# MCXN947_cm33_core0 register map
Vendor: nxp.com; File version: 1.0
CPU: CM33 r2p0, little endian, MPU, FPU, VTOR, 3 interrupt priority bits
Registers are 32-bit, read-write, reset 0x0 unless marked. A register's access mark holds for its fields unless they carry their own. Offsets are from the block's base; [hi:lo] are bit positions; {n}, {i} and the like mark numbered series; 'fields as' and 'values as' point back to an identical list.

## TDET0 — TDET
Base 0x40058000
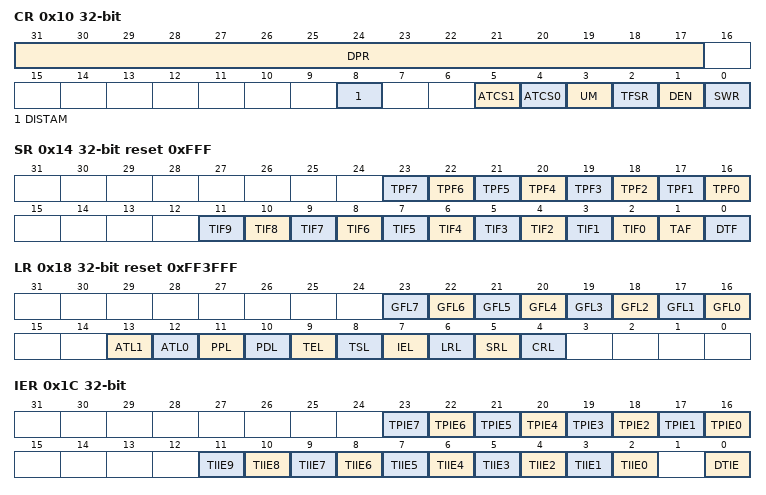
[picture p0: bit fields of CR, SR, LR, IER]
0x10 CR — Control
  [31:17] DPR — Digital Tamper Prescaler
  [8] DISTAM — Disable Prescaler On Tamper
    0=NO_EFFECT; 1=AUTO_DIS (Automatically disables the prescaler after tamper detection)
  [5] ATCS1 — Active Tamper Clock Source
    0=FREQ_1_HZ (1 Hz prescaler clock); 1=FREQ_64_HZ (64 Hz prescaler clock)
  [4] ATCS0 — Active Tamper Clock Source
    values as ATCS1
  [3] UM — Update Mode
    0=NO_EFFECT; 1=CLEAR_INTS (Allows the clearing of interrupts)
  [2] TFSR — Tamper Force System Reset
    0=NO_RESET (Do not force chip reset); 1=RESET (Force chip reset)
  [1] DEN — Digital Tamper Enable
    0=DISABLE (Disables TDET clock and prescaler); 1=ENABLE (Enables TDET clock and prescaler)
  [0] SWR — Software Reset
    0=NO_EFFECT; 1=SW_RESET (Perform a software reset)
0x14 SR reset 0xFFF write-1-clears — Status
  [n+16] TPF{n} write-1-clears (n=0..7) — Tamper Pin n Flag
    0=NO_DET (Pin tamper not detected); 1=DET (Pin tamper detected)
  [n+2] TIF{n} write-1-clears (n=0..9) — Tamper Input n Flag
    0=NO_DET (On-chip tamper not detected); 1=DET (On-chip tamper detected)
  [1] TAF write-1-clears — Tamper Acknowledge Flag
    0=NOT_OCCUR (Digital Tamper Flag (SR[DTF]) is clear or chip reset has not occurred after Digital Tamper Flag (SR[DTF]) was set.); 1=OCCUR (Chip reset has occurred after Digital Tamper Flag (SR[DTF]) was set.)
  [0] DTF write-1-clears — Digital Tamper Flag
    0=NO_DET (TDET tampering not detected); 1=DET (TDET tampering detected)
0x18 LR reset 0xFF3FFF — Lock
  [all] fields
    0=LOCK (Locked and writes are ignored); 1=NOT_LOCK (Not locked and writes complete as normal)
  [n+16] GFL{n} (n=0..7) — Glitch Filter Lock
  [13] ATL1 — Active Tamper Lock
  [12] ATL0 — Active Tamper Lock
  [11] PPL — Pin Polarity Lock
  [10] PDL — Pin Direction Lock
  [9] TEL — Tamper Enable Lock
  [8] TSL — Tamper Seconds Lock
  [7] IEL — Interrupt Enable Lock
  [6] LRL — Lock Register Lock
  [5] SRL — Status Register Lock
  [4] CRL — Control Register Lock
0x1C IER — Interrupt Enable
  [all] fields
    0=DISABLE (Disables); 1=ENABLE (Enables)
  [n+16] TPIE{n} (n=0..7) — Tamper Pin n Interrupt Enable
  [n+2] TIIE{n} (n=0..9) — Tamper Input n Interrupt Enable
  [0] DTIE — Digital Tamper Interrupt Enable
0x20 TSR — Tamper Seconds
  [31:0] TTS — Tamper Time Seconds
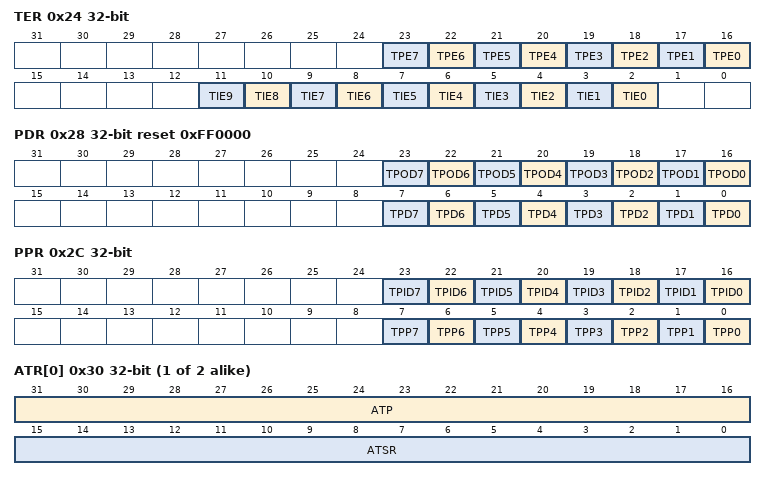
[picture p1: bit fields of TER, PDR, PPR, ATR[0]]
0x24 TER — Tamper Enable
  [all] fields
    0=DISABLE (Disables); 1=ENABLE (Enables)
  [n+16] TPE{n} (n=0..7) — Tamper Pin Enable
  [n+2] TIE{n} (n=0..9) — Tamper Input Enable
0x28 PDR reset 0xFF0000 — Pin Direction
  [n+16] TPOD{n} ro (n=0..7) — Tamper Pin Output Data
    0=ZERO; 1=ONE
  [n] TPD{n} (n=0..7) — Tamper Pin Direction
    0=INPUT; 1=OUTPUT (Output and drives the inverse of the expected value (tamper pin is asserted))
0x2C PPR — Pin Polarity
  [n+16] TPID{n} ro (n=0..7) — Tamper Pin n Input Data
    0=ZERO; 1=ONE
  [n] TPP{n} (n=0..7) — Tamper Pin n Polarity
    0=NO_INVERT (Not inverted); 1=INVERT (Inverted)
{0x30+4i} ATR[{i}] (i=0..1) — Active Tamper
  [31:16] ATP — Active Tamper Polynomial
  [15:0] ATSR — Active Tamper Shift Register
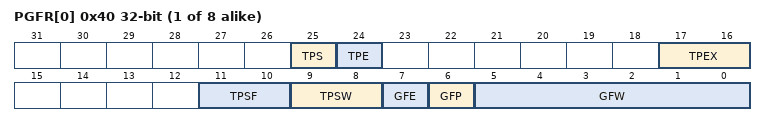
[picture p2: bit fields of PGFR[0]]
{0x40+4i} PGFR[{i}] (i=0..7) — Pin Glitch Filter
  [25] TPS — Tamper Pull Select
    0=ASSERT (Asserts); 1=NEGATE (Negates)
  [24] TPE — Tamper Pull Enable
    0=DISABLE (Disables); 1=ENABLE (Enables)
  [17:16] TPEX — Tamper Pin Expected
    0=ZERO (Zero/passive tamper); 1=VAL_TAMP0 (Active Tamper 0 output); 2=VAL_TAMP1 (Active Tamper 1 output); 3=TAMP0_XOR_TAMP1 (Active Tamper 0 output XORed with Active Tamper 1 output)
  [11:10] TPSF — Tamper Pin Sample Frequency
    0=CYCLES_8 (Every 8 cycles); 1=CYCLES_32 (Every 32 cycles); 2=CYCLES_128 (Every 128 cycles); 3=CYCLES_512 (Every 512 cycles)
  [9:8] TPSW — Tamper Pin Sample Width
    0=DISABLE (Continuous monitoring, pin sampling disabled); 1=CYCLES_2 (2 cycles for pull enable and 1 cycle for input buffer enable); 2=CYCLES_4 (4 cycles for pull enable and 2 cycles for input buffer enable); 3=CYCLES_8 (8 cycles for pull enable and 4 cycles for input buffer enable)
  [7] GFE — Glitch Filter Enable
    0=BYPASS (Bypasses); 1=ENABLE (Enables)
  [6] GFP — Glitch Filter Prescaler
    0=FREQ_512_HZ (512 Hz prescaler clock); 1=FREQ_32_KHZ (32.768 kHz clock)
  [5:0] GFW — Glitch Filter Width
